# STM32F7x2_v1r0 register map
File version: 1.0
Registers are 32-bit, read-write, reset 0x0 unless marked. A register's access mark holds for its fields unless they carry their own. Offsets are from the block's base; [hi:lo] are bit positions; {n}, {i} and the like mark numbered series.

## DAC — Digital-to-analog converter
Base 0x40007400
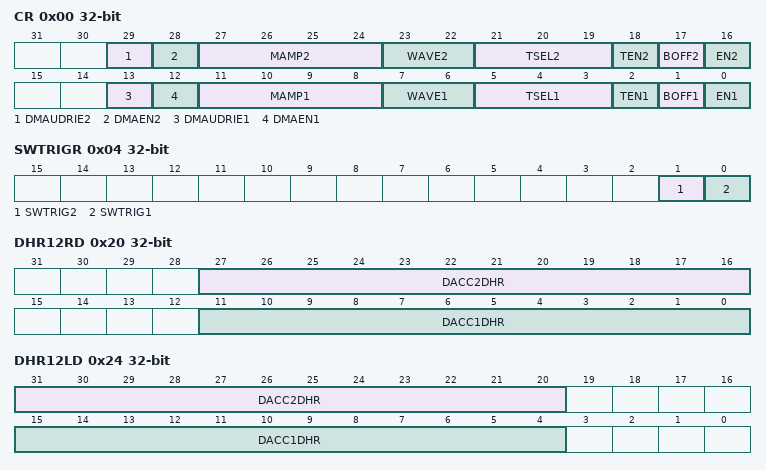
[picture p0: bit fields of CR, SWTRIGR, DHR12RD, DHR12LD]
0x00 CR — control register
  [29] DMAUDRIE2 — DAC channel2 DMA underrun interrupt enable
  [28] DMAEN2 — DAC channel2 DMA enable
  [27:24] MAMP2 — DAC channel2 mask/amplitude selector
  [23:22] WAVE2 — DAC channel2 noise/triangle wave generation enable
  [21:19] TSEL2 — DAC channel2 trigger selection
  [18] TEN2 — DAC channel2 trigger enable
  [17] BOFF2 — DAC channel2 output buffer disable
  [16] EN2 — DAC channel2 enable
  [13] DMAUDRIE1 — DAC channel1 DMA Underrun Interrupt enable
  [12] DMAEN1 — DAC channel1 DMA enable
  [11:8] MAMP1 — DAC channel1 mask/amplitude selector
  [7:6] WAVE1 — DAC channel1 noise/triangle wave generation enable
  [5:3] TSEL1 — DAC channel1 trigger selection
  [2] TEN1 — DAC channel1 trigger enable
  [1] BOFF1 — DAC channel1 output buffer disable
  [0] EN1 — DAC channel1 enable
0x04 SWTRIGR wo — software trigger register
  [1] SWTRIG2 — DAC channel2 software trigger
  [0] SWTRIG1 — DAC channel1 software trigger
0x08 DHR12R1 — channel1 12-bit right-aligned data holding register
  [11:0] DACC1DHR — DAC channel1 12-bit right-aligned data
0x0C DHR12L1 — channel1 12-bit left aligned data holding register
  [15:4] DACC1DHR — DAC channel1 12-bit left-aligned data
0x10 DHR8R1 — channel1 8-bit right aligned data holding register
  [7:0] DACC1DHR — DAC channel1 8-bit right-aligned data
0x14 DHR12R2 — channel2 12-bit right aligned data holding register
  [11:0] DACC2DHR — DAC channel2 12-bit right-aligned data
0x18 DHR12L2 — channel2 12-bit left aligned data holding register
  [15:4] DACC2DHR — DAC channel2 12-bit left-aligned data
0x1C DHR8R2 — channel2 8-bit right-aligned data holding register
  [7:0] DACC2DHR — DAC channel2 8-bit right-aligned data
0x20 DHR12RD — Dual DAC 12-bit right-aligned data holding register
  [27:16] DACC2DHR — DAC channel2 12-bit right-aligned data
  [11:0] DACC1DHR — DAC channel1 12-bit right-aligned data
0x24 DHR12LD — DUAL DAC 12-bit left aligned data holding register
  [31:20] DACC2DHR — DAC channel2 12-bit left-aligned data
  [15:4] DACC1DHR — DAC channel1 12-bit left-aligned data
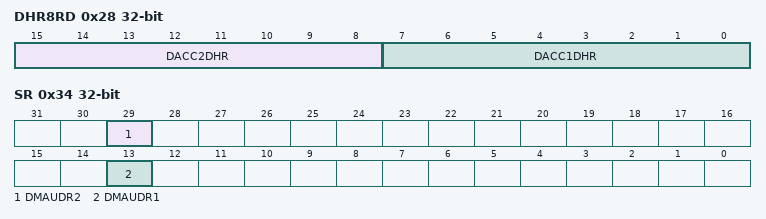
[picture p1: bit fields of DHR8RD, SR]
0x28 DHR8RD — DUAL DAC 8-bit right aligned data holding register
  [15:8] DACC2DHR — DAC channel2 8-bit right-aligned data
  [7:0] DACC1DHR — DAC channel1 8-bit right-aligned data
0x2C DOR1 ro — channel1 data output register
  [11:0] DACC1DOR — DAC channel1 data output
0x30 DOR2 ro — channel2 data output register
  [11:0] DACC2DOR — DAC channel2 data output
0x34 SR — status register
  [29] DMAUDR2 — DAC channel2 DMA underrun flag
  [13] DMAUDR1 — DAC channel1 DMA underrun flag

## EXTI — External interrupt/event controller
Base 0x40013C00
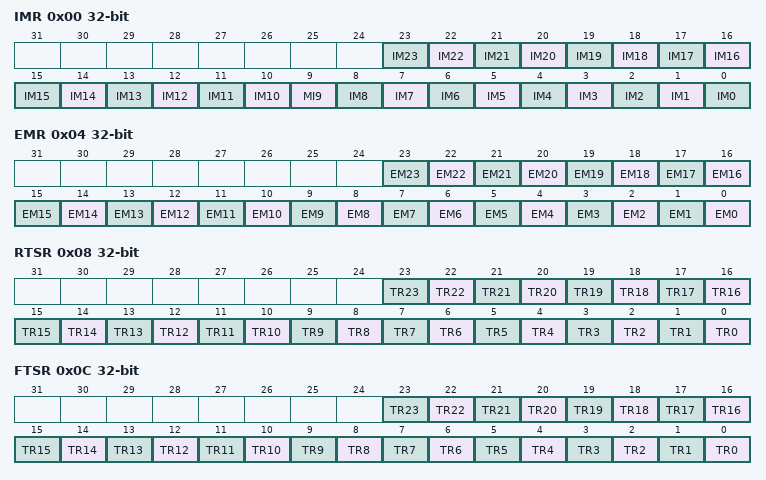
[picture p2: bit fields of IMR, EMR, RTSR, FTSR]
0x00 IMR — Interrupt mask register (EXTI_IMR)
  [n] IM{n} (n=10..23) — Interrupt Mask on line {n}
  [9] MI9 — Interrupt Mask on line 9
  [n] IM{n} (n=0..8) — Interrupt Mask on line {n}
0x04 EMR — Event mask register (EXTI_EMR)
  [n] EM{n} (n=0..23) — Event Mask on line {n}
0x08 RTSR — Rising Trigger selection register (EXTI_RTSR)
  [n] TR{n} (n=0..23) — Rising trigger event configuration of line {n}
0x0C FTSR — Falling Trigger selection register (EXTI_FTSR)
  [n] TR{n} (n=0..23) — Falling trigger event configuration of line {n}
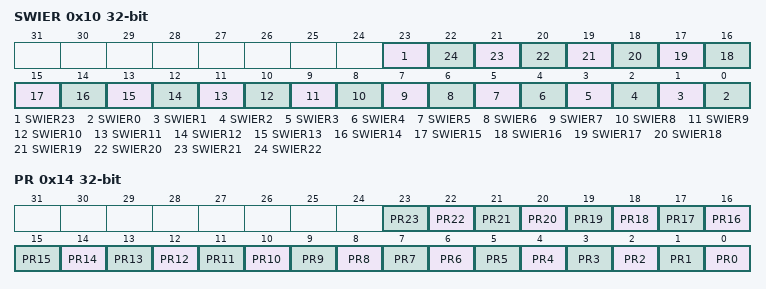
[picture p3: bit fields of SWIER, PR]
0x10 SWIER — Software interrupt event register (EXTI_SWIER)
  [23] SWIER23 — Software Interrupt on line 22
  [n] SWIER{n} (n=0..22) — Software Interrupt on line {n}
0x14 PR — Pending register (EXTI_PR)
  [n] PR{n} (n=0..23) — Pending bit {n}

## FLASH
Base 0x40023C00
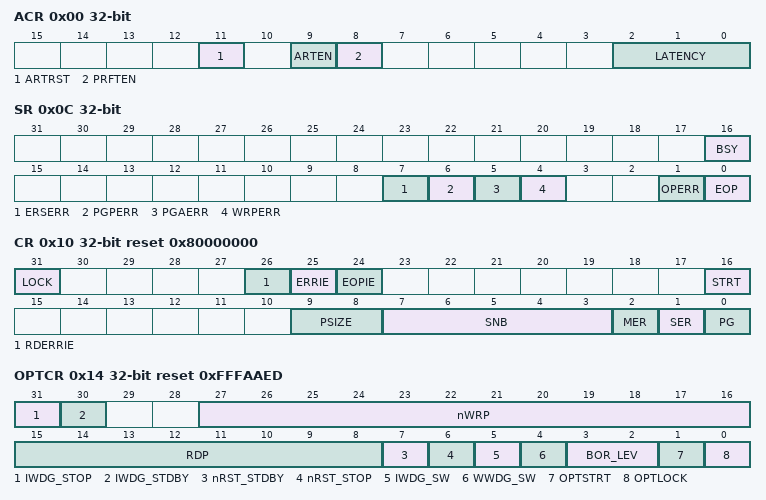
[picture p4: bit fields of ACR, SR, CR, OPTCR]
0x00 ACR — Flash access control register
  [11] ARTRST — ART Accelerator reset
  [9] ARTEN — ART Accelerator Enable
  [8] PRFTEN — Prefetch enable
  [2:0] LATENCY
0x04 KEYR wo — Flash key register
  [31:0] KEY — FPEC key
0x08 OPTKEYR wo — Flash option key register
  [31:0] OPTKEYR — Option byte key
0x0C SR access per field — Status register
  [16] BSY ro — Busy
  [7] ERSERR rw — Erase Sequence Error
  [6] PGPERR rw — Programming parallelism error
  [5] PGAERR rw — Programming alignment error
  [4] WRPERR rw — Write protection error
  [1] OPERR rw — Operation error
  [0] EOP rw — End of operation
0x10 CR reset 0x80000000 — Control register
  [31] LOCK
  [26] RDERRIE — PCROP error interrupt enable
  [25] ERRIE — Error interrupt enable
  [24] EOPIE — End of operation interrupt enable
  [16] STRT — Start
  [9:8] PSIZE — Program size
  [7:3] SNB — Sector number
  [2] MER — Mass Erase of sectors 0 to 11
  [1] SER — Sector Erase
  [0] PG — Programming
0x14 OPTCR reset 0xFFFAAED — Flash option control register
  [31] IWDG_STOP — Independent watchdog counter freeze in Stop mode
  [30] IWDG_STDBY — Independent watchdog counter freeze in standby mode
  [27:16] nWRP — Not write protect
  [15:8] RDP — Read protect
  [7] nRST_STDBY — nRST_STDBY User option bytes
  [6] nRST_STOP — nRST_STOP User option bytes
  [5] IWDG_SW — WDG_SW User option bytes
  [4] WWDG_SW — User option bytes
  [3:2] BOR_LEV — BOR reset Level
  [1] OPTSTRT — Option start
  [0] OPTLOCK — Option lock
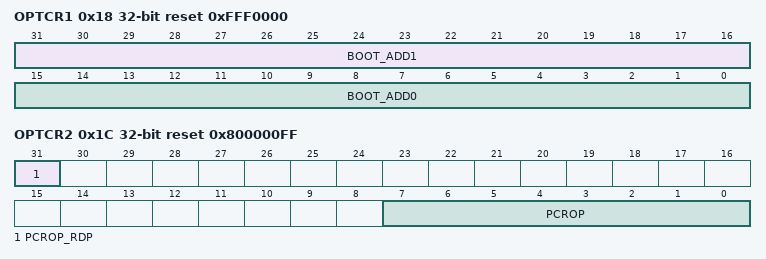
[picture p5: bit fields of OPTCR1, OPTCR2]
0x18 OPTCR1 reset 0xFFF0000 — Flash option control register 1
  [31:16] BOOT_ADD1 — Boot base address when Boot pin =1
  [15:0] BOOT_ADD0 — Boot base address when Boot pin =0
0x1C OPTCR2 reset 0x800000FF — Flash option control register
  [31] PCROP_RDP — PCROP zone preserved when RDP level decreased
  [7:0] PCROP — PCROP option byte
